# ATSAMC20J17AU register map
Vendor: Atmel Corporation; Series: SAMC20; File version: C
CPU: CM0+ r0p1, little endian, MPU, no FPU, VTOR, 2 interrupt priority bits
Registers are 32-bit, read-write, reset 0x0 unless marked. A register's access mark holds for its fields unless they carry their own. Offsets are from the block's base; [hi:lo] are bit positions; {n}, {i} and the like mark numbered series; 'fields as' and 'values as' point back to an identical list.

## PM — Power Manager
Base 0x40000400; register names take the prefix PM_
0x01 SLEEPCFG 8-bit — Sleep Configuration
  [2:0] SLEEPMODE
    0=IDLE0 (CPU clock is OFF); 1=IDLE1 (AHB clock is OFF); 2=IDLE2 (APB clock are OFF); 4=STANDBY (All Clocks are OFF)
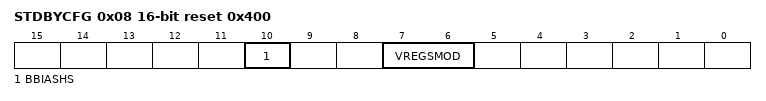
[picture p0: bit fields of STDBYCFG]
0x08 STDBYCFG 16-bit reset 0x400 — Standby Configuration
  [10] BBIASHS — Back Bias for HMCRAMCHS
  [7:6] VREGSMOD — Voltage Regulator Standby mode
    0=AUTO (Automatic mode); 1=PERFORMANCE (Performance oriented); 2=LP (Low Power oriented)

## PORT — Port Module
Base 0x41000000; register names take the prefix PORT_
Same registers: PORT_IOBUS 0x60000000 (register names take the prefix PORT_IOBUS_)
{0x0+0x80*i} DIR{i} (i=0..1) — Data Direction
{0x4+0x80*i} DIRCLR{i} (i=0..1) — Data Direction Clear
{0x8+0x80*i} DIRSET{i} (i=0..1) — Data Direction Set
{0xC+0x80*i} DIRTGL{i} (i=0..1) — Data Direction Toggle
{0x10+0x80*i} OUT{i} (i=0..1) — Data Output Value
{0x14+0x80*i} OUTCLR{i} (i=0..1) — Data Output Value Clear
{0x18+0x80*i} OUTSET{i} (i=0..1) — Data Output Value Set
{0x1C+0x80*i} OUTTGL{i} (i=0..1) — Data Output Value Toggle
{0x20+0x80*i} IN{i} (i=0..1) ro — Data Input Value
{0x24+0x80*i} CTRL{i} (i=0..1) — Control
  [31:0] SAMPLING wo — Input Sampling Mode
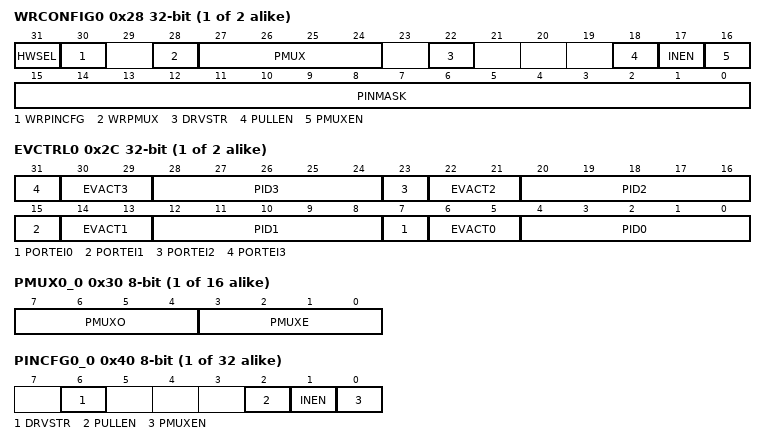
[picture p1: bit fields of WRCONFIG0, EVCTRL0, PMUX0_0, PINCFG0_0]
{0x28+0x80*i} WRCONFIG{i} (i=0..1) wo — Write Configuration
  [31] HWSEL — Half-Word Select
  [30] WRPINCFG — Write PINCFG Registers
  [28] WRPMUX — Write PMUX Registers
  [27:24] PMUX — Peripheral Multiplexing Template
  [22] DRVSTR — Output Driver Strength Selection
  [18] PULLEN — Pull Enable
  [17] INEN — Input Enable
  [16] PMUXEN — Select Peripheral Multiplexer
  [15:0] PINMASK — Pin Mask for Multiple Pin Configuration
{0x2C+0x80*i} EVCTRL{i} (i=0..1) — Event Input Control
  [8n+7] PORTEI{n} (n=0..3) — Port Event Enable Input {n}
  [30:29] EVACT3 — Port Event Action 3
  [8n+4:8n] PID{n} (n=0..3) — Port Event Pin Identifier {n}
  [22:21] EVACT2 — Port Event Action 2
  [14:13] EVACT1 — Port Event Action 1
  [6:5] EVACT0 — Port Event Action 0
    0=OUT (Event output to pin); 1=SET (Set output register of pin on event); 2=CLR (Clear output register of pin on event); 3=TGL (Toggle output register of pin on event)
{0x30+i} PMUX0_{i} (i=0..15) 8-bit — Peripheral Multiplexing n - Group 0
  [7:4] PMUXO — Peripheral Multiplexing for Odd-Numbered Pin
  [3:0] PMUXE — Peripheral Multiplexing for Even-Numbered Pin
{0x40+i} PINCFG0_{i} (i=0..31) 8-bit — Pin Configuration n - Group 0
  [6] DRVSTR wo — Output Driver Strength Selection
  [2] PULLEN — Pull Enable
  [1] INEN — Input Enable
  [0] PMUXEN — Select Peripheral Multiplexer
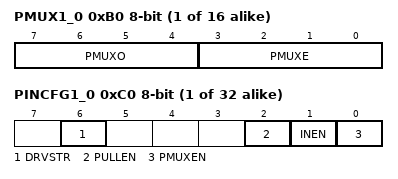
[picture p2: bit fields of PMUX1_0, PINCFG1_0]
{0xB0+i} PMUX1_{i} (i=0..15) 8-bit — Peripheral Multiplexing n - Group 1
  fields as PMUX0_0
{0xC0+i} PINCFG1_{i} (i=0..31) 8-bit — Pin Configuration n - Group 1
  fields as PINCFG0_0

## RSTC — Reset Controller
Base 0x40000C00; register names take the prefix RSTC_
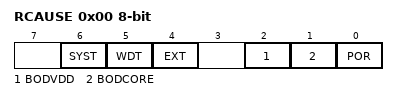
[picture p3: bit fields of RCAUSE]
0x00 RCAUSE 8-bit ro — Reset Cause
  [6] SYST — System Reset Request
  [5] WDT — Watchdog Reset
  [4] EXT — External Reset
  [2] BODVDD — Brown Out VDD Detector Reset
  [1] BODCORE — Brown Out CORE Detector Reset
  [0] POR — Power On Reset

## SUPC — Supply Controller
Base 0x40001800; register names take the prefix SUPC_
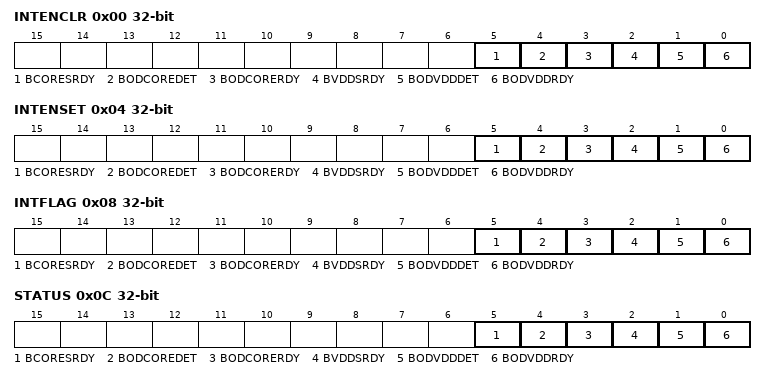
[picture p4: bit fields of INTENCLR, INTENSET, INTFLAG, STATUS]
0x00 INTENCLR — Interrupt Enable Clear
  [5] BCORESRDY — BODCORE Synchronization Ready
  [4] BODCOREDET — BODCORE Detection
  [3] BODCORERDY — BODCORE Ready
  [2] BVDDSRDY — BODVDD Synchronization Ready
  [1] BODVDDDET — BODVDD Detection
  [0] BODVDDRDY — BODVDD Ready
0x04 INTENSET — Interrupt Enable Set
  fields as INTENCLR
0x08 INTFLAG — Interrupt Flag Status and Clear
  fields as INTENCLR
0x0C STATUS ro — Power and Clocks Status
  fields as INTENCLR
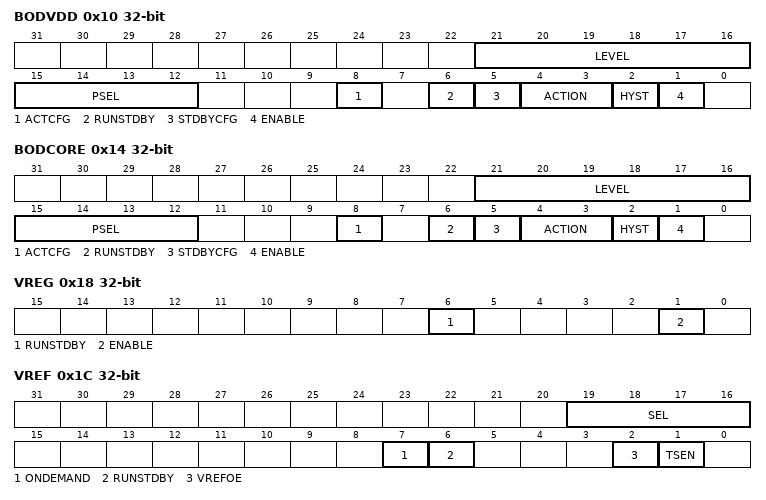
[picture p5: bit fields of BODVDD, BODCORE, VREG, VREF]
0x10 BODVDD — BODVDD Control
  [21:16] LEVEL — Threshold Level for VDD
  [15:12] PSEL — Prescaler Select
    0=DIV2 (Divide clock by 2); 1=DIV4 (Divide clock by 4); 2=DIV8 (Divide clock by 8); 3=DIV16 (Divide clock by 16); 4=DIV32 (Divide clock by 32); 5=DIV64 (Divide clock by 64); 6=DIV128 (Divide clock by 128); 7=DIV256 (Divide clock by 256); 8=DIV512 (Divide clock by 512); 9=DIV1024 (Divide clock by 1024); 10=DIV2048 (Divide clock by 2048); 11=DIV4096 (Divide clock by 4096); 12=DIV8192 (Divide clock by 8192); 13=DIV16384 (Divide clock by 16384); 14=DIV32768 (Divide clock by 32768); 15=DIV65536 (Divide clock by 65536)
  [8] ACTCFG — Configuration in Active mode
  [6] RUNSTDBY — Run during Standby
  [5] STDBYCFG — Configuration in Standby mode
  [4:3] ACTION — Action when Threshold Crossed
    0=NONE (No action); 1=RESET (The BOD33 generates a reset); 2=INT (The BOD33 generates an interrupt)
  [2] HYST — Hysteresis Enable
  [1] ENABLE
0x14 BODCORE — BODCORE Control
  [21:16] LEVEL — Threshold Level
  [15:12] PSEL — Prescaler Select
    values as BODVDD.PSEL
  [8] ACTCFG — Configuration in Active mode
  [6] RUNSTDBY — Run during Standby
  [5] STDBYCFG — Configuration in Standby mode
  [4:3] ACTION — Action when Threshold Crossed
    0=NONE (No action); 1=RESET (The BOD12 generates a reset); 2=INT (The BOD12 generates an interrupt)
  [2] HYST — Hysteresis Enable
  [1] ENABLE
0x18 VREG — VREG Control
  [6] RUNSTDBY — Run during Standby
  [1] ENABLE
0x1C VREF — VREF Control
  [19:16] SEL — Voltage Reference Selection
    0=1V024 (1.024V voltage reference typical value); 2=2V048 (2.048V voltage reference typical value); 3=4V096 (4.096V voltage reference typical value)
  [7] ONDEMAND — On Demand Contrl
  [6] RUNSTDBY — Run during Standby
  [2] VREFOE — Voltage Reference Output Enable
  [1] TSEN — Temperature Sensor Output Enable

## TAL — Trigger Allocator
Base 0x42006000; register names take the prefix TAL_
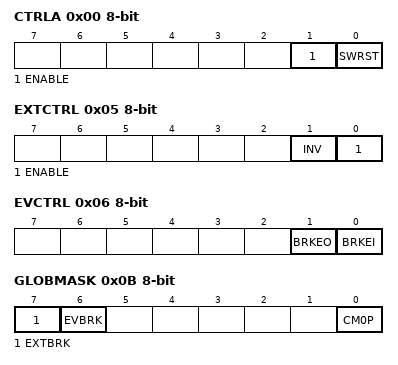
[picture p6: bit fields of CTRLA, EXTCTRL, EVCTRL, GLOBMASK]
0x00 CTRLA 8-bit — Control A
  [1] ENABLE
  [0] SWRST — Software Reset
0x04 RSTCTRL 8-bit — Reset Control
0x05 EXTCTRL 8-bit — External Break Control
  [1] INV — Invert BRK Pin
  [0] ENABLE — Enable BRK Pin
0x06 EVCTRL 8-bit — Event Control
  [1] BRKEO — Break Output Event Enable
  [0] BRKEI — Break Input Event Enable
0x08 INTENCLR 8-bit — Interrupt Enable Clear
  [0] BRK — Break Interrupt Enable
0x09 INTENSET 8-bit — Interrupt Enable Set
  [0] BRK — Break Interrupt Enable
0x0A INTFLAG 8-bit — Interrupt Flag Status and Clear
  [0] BRK — Break
0x0B GLOBMASK 8-bit — Global Break Requests Mask
  [7] EXTBRK — External Break Master
  [6] EVBRK — Event Break Master
  [0] CM0P — CM0P Break Master
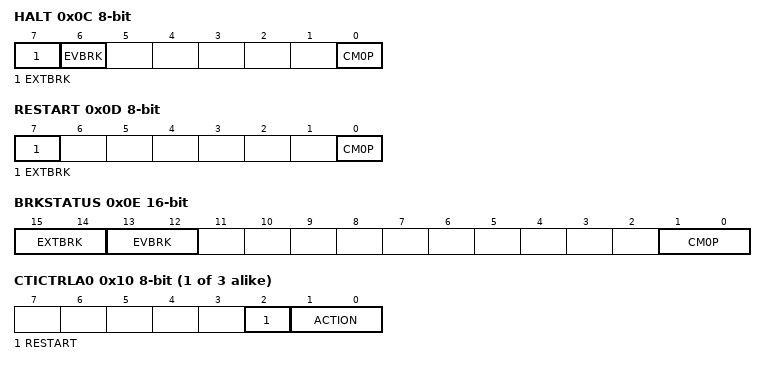
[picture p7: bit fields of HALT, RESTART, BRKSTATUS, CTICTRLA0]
0x0C HALT 8-bit wo — Debug Halt Request
  fields as GLOBMASK
0x0D RESTART 8-bit wo — Debug Restart Request
  [7] EXTBRK — External Break Master
  [0] CM0P — CM0P Break Master
0x0E BRKSTATUS 16-bit ro — Break Request Status
  [15:14] EXTBRK — External Break Request
  [13:12] EVBRK — Event Break Request
  [1:0] CM0P — CM0P Break Request
{0x10+2i} CTICTRLA{i} (i=0..2) 8-bit — Cross-Trigger Interface n Control A
  [2] RESTART — Action when global restart issued
  [1:0] ACTION — Action when global break issued
    0=BREAK (Break when requested); 1=INTERRUPT (Trigger DBG interrupt instead of break); 2=IGNORE (Ignore break request)
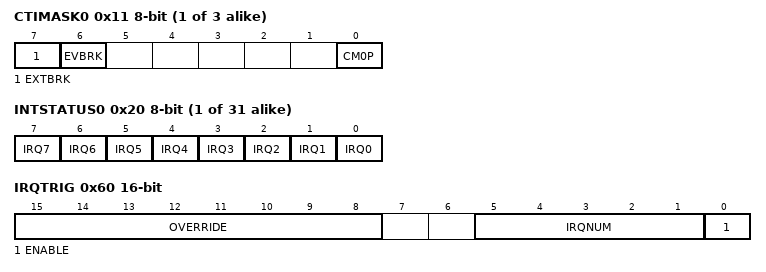
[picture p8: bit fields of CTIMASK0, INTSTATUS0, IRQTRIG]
{0x11+2i} CTIMASK{i} (i=0..2) 8-bit — Cross-Trigger Interface n Mask
  fields as GLOBMASK
{0x20+i} INTSTATUS{i} (i=0..30) 8-bit ro — Interrupt n Status
  [n] IRQ{n} (n=0..7) — Interrupt Status for Interrupt Request {n} within Interrupt n
0x60 IRQTRIG 16-bit — Interrupt Trigger
  [15:8] OVERRIDE — Interrupt Request Override Value
  [5:1] IRQNUM — Interrupt Request Number
  [0] ENABLE — Trigger Enable
{0x64+4i} CPUIRQS{i} (i=0..0) ro — Interrupt Status for CPU n
  [30:0] CPUIRQS — Interrupt Requests for CPU n

## WDT — Watchdog Timer
Base 0x40002000; register names take the prefix WDT_
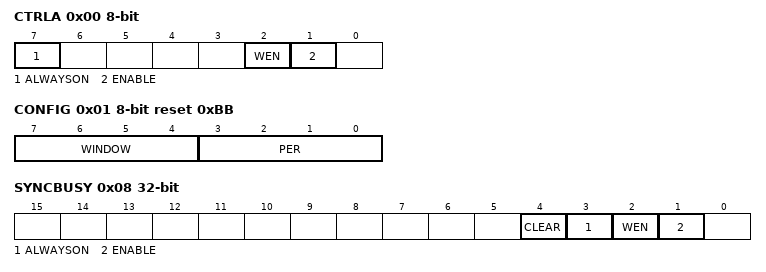
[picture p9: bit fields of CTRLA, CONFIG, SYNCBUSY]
0x00 CTRLA 8-bit — Control
  [7] ALWAYSON
  [2] WEN — Watchdog Timer Window Mode Enable
  [1] ENABLE
0x01 CONFIG 8-bit reset 0xBB — Configuration
  [7:4] WINDOW — Window Mode Time-Out Period
    0=CYC8 (8 clock cycles); 1=CYC16 (16 clock cycles); 2=CYC32 (32 clock cycles); 3=CYC64 (64 clock cycles); 4=CYC128 (128 clock cycles); 5=CYC256 (256 clock cycles); 6=CYC512 (512 clock cycles); 7=CYC1024 (1024 clock cycles); 8=CYC2048 (2048 clock cycles); 9=CYC4096 (4096 clock cycles); 10=CYC8192 (8192 clock cycles); 11=CYC16384 (16384 clock cycles)
  [3:0] PER — Time-Out Period
    values as WINDOW
0x02 EWCTRL 8-bit reset 0xB — Early Warning Interrupt Control
  [3:0] EWOFFSET — Early Warning Interrupt Time Offset
    values as CONFIG.WINDOW
0x04 INTENCLR 8-bit — Interrupt Enable Clear
  [0] EW — Early Warning Interrupt Enable
0x05 INTENSET 8-bit — Interrupt Enable Set
  [0] EW — Early Warning Interrupt Enable
0x06 INTFLAG 8-bit — Interrupt Flag Status and Clear
  [0] EW — Early Warning
0x08 SYNCBUSY ro — Synchronization Busy
  [4] CLEAR — Clear Busy
  [3] ALWAYSON — Always-On Busy
  [2] WEN — Window Enable Busy
  [1] ENABLE — Enable Busy
0x0C CLEAR 8-bit wo
  [7:0] CLEAR — Watchdog Clear
    165=KEY (Clear Key)

## Notices in the file
Atmel Microcontroller Software Support
Copyright (c) 2017 Atmel Corporation,
a wholly owned subsidiary of Microchip Technology Inc.
Licensed under the Apache License, Version 2.0 (the "License");
you may not use this file except in compliance with the License.
You may obtain a copy of the Licence at
http://www.apache.org/licenses/LICENSE-2.0
Unless required by applicable law or agreed to in writing, software
distributed under the License is distributed on an "AS IS" BASIS,
WITHOUT WARRANTIES OR CONDITIONS OF ANY KIND, either express or implied.
See the License for the specific language governing permissions and
limitations under the License.
